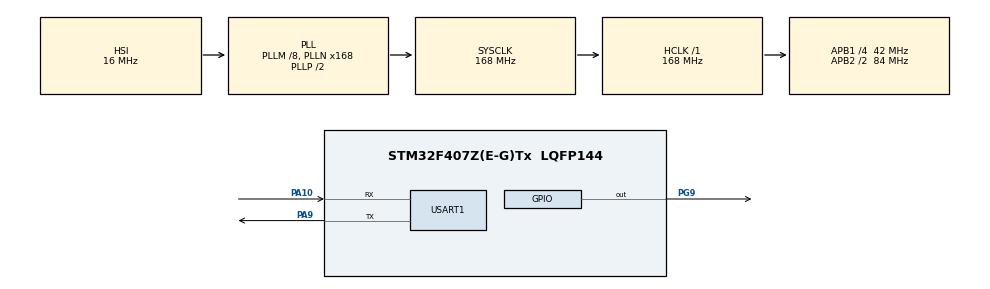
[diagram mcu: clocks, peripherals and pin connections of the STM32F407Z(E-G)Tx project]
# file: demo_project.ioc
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Mcu.Family=STM32F4
Mcu.Name=STM32F407Z(E-G)Tx
Mcu.Package=LQFP144
NVIC.PriorityGroup=NVIC_PRIORITYGROUP_4
NVIC.USART1_IRQn=true\:0\:0\:false\:false\:true\:true\:true
PA10.Mode=Asynchronous
PA10.Signal=USART1_RX
PA9.Mode=Asynchronous
PA9.Signal=USART1_TX
PG9.Signal=GPIO_Output
PH0-OSC_IN.Mode=HSE-External-Oscillator
PH0-OSC_IN.Signal=RCC_OSC_IN
PH1-OSC_OUT.Mode=HSE-External-Oscillator
PH1-OSC_OUT.Signal=RCC_OSC_OUT
ProjectManager.HeapSize=0x2000
ProjectManager.StackSize=0x800
ProjectManager.TargetToolchain=MDK-ARM V5
RCC.48MHZClocksFreq_Value=84000000
RCC.AHBFreq_Value=168000000
RCC.APB1CLKDivider=RCC_HCLK_DIV4
RCC.APB1Freq_Value=42000000
RCC.APB1TimFreq_Value=84000000
RCC.APB2CLKDivider=RCC_HCLK_DIV2
RCC.APB2Freq_Value=84000000
RCC.APB2TimFreq_Value=168000000
RCC.CortexFreq_Value=168000000
RCC.HCLKFreq_Value=168000000
RCC.HSE_VALUE=8000000
RCC.HSI_VALUE=16000000
RCC.LSE_VALUE=32768
RCC.PLLM=8
RCC.PLLN=168
RCC.SYSCLKFreq_VALUE=168000000
RCC.SYSCLKSource=RCC_SYSCLKSOURCE_PLLCLK
RCC.VCOOutputFreq_Value=336000000
STMicroelectronics.X-CUBE-AI.5.0.0.ActivationBufferSizeList=24576
STMicroelectronics.X-CUBE-AI.5.0.0.ApplicationCcArtificialOoIntelligenceJjApplication=Validation
STMicroelectronics.X-CUBE-AI.5.0.0.ArtificialOoIntelligenceJjApplication.cmp_version0=5.0.0
STMicroelectronics.X-CUBE-AI.5.0.0.ArtificialOoIntelligenceJjApplication.component0=Artificial Intelligence
STMicroelectronics.X-CUBE-AI.5.0.0.ArtificialOoIntelligenceJjApplication.description0=AI Application,Validation on Target
STMicroelectronics.X-CUBE-AI.5.0.0.ArtificialOoIntelligenceJjApplication.diagnostic0=This component should operate correctly.
STMicroelectronics.X-CUBE-AI.5.0.0.ArtificialOoIntelligenceJjApplication.documentation0=Documentation/index.html
STMicroelectronics.X-CUBE-AI.5.0.0.ArtificialOoIntelligenceJjApplication.group0=Application
STMicroelectronics.X-CUBE-AI.5.0.0.ArtificialOoIntelligenceJjApplication.paramName0=ApplicationCcArtificialOoIntelligenceJjApplication
STMicroelectronics.X-CUBE-AI.5.0.0.ArtificialOoIntelligenceJjApplication.sevirity0=none
STMicroelectronics.X-CUBE-AI.5.0.0.ArtificialOoIntelligenceJjApplication.variant0=Validation
STMicroelectronics.X-CUBE-AI.5.0.0.ArtificialOoIntelligenceJjApplication_bundle=Application
STMicroelectronics.X-CUBE-AI.5.0.0.ArtificialOoIntelligenceJjApplication_class=ArtificialOoIntelligence
STMicroelectronics.X-CUBE-AI.5.0.0.ArtificialOoIntelligenceJjApplication_name=X-CUBE-AI
STMicroelectronics.X-CUBE-AI.5.0.0.ArtificialOoIntelligenceJjApplication_size=1
STMicroelectronics.X-CUBE-AI.5.0.0.ArtificialOoIntelligenceJjApplication_vendor=STMicroelectronics
STMicroelectronics.X-CUBE-AI.5.0.0.ArtificialOoIntelligenceJjApplication_version=5.0.0
STMicroelectronics.X-CUBE-AI.5.0.0.ArtificialOoIntelligenceJjXAaCUBEAaAI.cmp_version0=5.0.0
STMicroelectronics.X-CUBE-AI.5.0.0.ArtificialOoIntelligenceJjXAaCUBEAaAI.cmp_version1=5.0.0
STMicroelectronics.X-CUBE-AI.5.0.0.ArtificialOoIntelligenceJjXAaCUBEAaAI.component0=Artificial Intelligence
STMicroelectronics.X-CUBE-AI.5.0.0.ArtificialOoIntelligenceJjXAaCUBEAaAI.component1=Artificial Intelligence
STMicroelectronics.X-CUBE-AI.5.0.0.ArtificialOoIntelligenceJjXAaCUBEAaAI.componentDoc0=nofile
STMicroelectronics.X-CUBE-AI.5.0.0.ArtificialOoIntelligenceJjXAaCUBEAaAI.description0=AI Core,Artificial Intelligence for STM32
STMicroelectronics.X-CUBE-AI.5.0.0.ArtificialOoIntelligenceJjXAaCUBEAaAI.description1=AI Application,Validation on Target
STMicroelectronics.X-CUBE-AI.5.0.0.ArtificialOoIntelligenceJjXAaCUBEAaAI.diagnostic0=This component should operate correctly.
STMicroelectronics.X-CUBE-AI.5.0.0.ArtificialOoIntelligenceJjXAaCUBEAaAI.diagnostic1=This component should operate correctly.
STMicroelectronics.X-CUBE-AI.5.0.0.ArtificialOoIntelligenceJjXAaCUBEAaAI.documentation0=Documentation/index.html
STMicroelectronics.X-CUBE-AI.5.0.0.ArtificialOoIntelligenceJjXAaCUBEAaAI.documentation1=Documentation/index.html
STMicroelectronics.X-CUBE-AI.5.0.0.ArtificialOoIntelligenceJjXAaCUBEAaAI.group0=Core
STMicroelectronics.X-CUBE-AI.5.0.0.ArtificialOoIntelligenceJjXAaCUBEAaAI.group1=Application
STMicroelectronics.X-CUBE-AI.5.0.0.ArtificialOoIntelligenceJjXAaCUBEAaAI.paramName0=XAaCUBEAaAICcArtificialOoIntelligenceJjCore
STMicroelectronics.X-CUBE-AI.5.0.0.ArtificialOoIntelligenceJjXAaCUBEAaAI.paramName1=ApplicationCcArtificialOoIntelligenceJjApplication
STMicroelectronics.X-CUBE-AI.5.0.0.ArtificialOoIntelligenceJjXAaCUBEAaAI.sevirity0=none
STMicroelectronics.X-CUBE-AI.5.0.0.ArtificialOoIntelligenceJjXAaCUBEAaAI.sevirity1=none
STMicroelectronics.X-CUBE-AI.5.0.0.ArtificialOoIntelligenceJjXAaCUBEAaAI.variant1=Validation
STMicroelectronics.X-CUBE-AI.5.0.0.ArtificialOoIntelligenceJjXAaCUBEAaAI_bundle=X-CUBE-AI
STMicroelectronics.X-CUBE-AI.5.0.0.ArtificialOoIntelligenceJjXAaCUBEAaAI_class=ArtificialOoIntelligence
STMicroelectronics.X-CUBE-AI.5.0.0.ArtificialOoIntelligenceJjXAaCUBEAaAI_name=X-CUBE-AI
STMicroelectronics.X-CUBE-AI.5.0.0.ArtificialOoIntelligenceJjXAaCUBEAaAI_size=2
STMicroelectronics.X-CUBE-AI.5.0.0.ArtificialOoIntelligenceJjXAaCUBEAaAI_vendor=STMicroelectronics
STMicroelectronics.X-CUBE-AI.5.0.0.ArtificialOoIntelligenceJjXAaCUBEAaAI_version=5.0.0
STMicroelectronics.X-CUBE-AI.5.0.0.BSP.number=1
STMicroelectronics.X-CUBE-AI.5.0.0.HeapSize=0x2000
STMicroelectronics.X-CUBE-AI.5.0.0.InternalRamActivationBufferMaxSize=AI_NETWORK_DATA_ACTIVATIONS_SIZE
STMicroelectronics.X-CUBE-AI.5.0.0.LatestDirectoryUsed-1c7994f23170c33a6f3a2a37c353d476fe9b7e1d63af1343e5945bc54d5a9b8a=C\:\\Users\\40561\\Desktop
STMicroelectronics.X-CUBE-AI.5.0.0.MaximumNumberOfInputLayer=1
STMicroelectronics.X-CUBE-AI.5.0.0.MaximumNumberOfOutputLayer=1
STMicroelectronics.X-CUBE-AI.5.0.0.MaximumSizeOfInputLayer=1080
STMicroelectronics.X-CUBE-AI.5.0.0.MaximumSizeOfOutputLayer=24
STMicroelectronics.X-CUBE-AI.5.0.0.ModelActualCompression-1c7994f23170c33a6f3a2a37c353d476fe9b7e1d63af1343e5945bc54d5a9b8a=0.0
STMicroelectronics.X-CUBE-AI.5.0.0.ModelCompression-1c7994f23170c33a6f3a2a37c353d476fe9b7e1d63af1343e5945bc54d5a9b8a=8
STMicroelectronics.X-CUBE-AI.5.0.0.ModelFlashOccupation-1c7994f23170c33a6f3a2a37c353d476fe9b7e1d63af1343e5945bc54d5a9b8a=375448
STMicroelectronics.X-CUBE-AI.5.0.0.ModelHashList=1c7994f23170c33a6f3a2a37c353d476fe9b7e1d63af1343e5945bc54d5a9b8a
STMicroelectronics.X-CUBE-AI.5.0.0.ModelKind-1c7994f23170c33a6f3a2a37c353d476fe9b7e1d63af1343e5945bc54d5a9b8a=KERAS
STMicroelectronics.X-CUBE-AI.5.0.0.ModelMacc-1c7994f23170c33a6f3a2a37c353d476fe9b7e1d63af1343e5945bc54d5a9b8a=874970
STMicroelectronics.X-CUBE-AI.5.0.0.ModelName-1c7994f23170c33a6f3a2a37c353d476fe9b7e1d63af1343e5945bc54d5a9b8a=network
STMicroelectronics.X-CUBE-AI.5.0.0.ModelNameList=network
STMicroelectronics.X-CUBE-AI.5.0.0.ModelRamOccupation-1c7994f23170c33a6f3a2a37c353d476fe9b7e1d63af1343e5945bc54d5a9b8a=24576
STMicroelectronics.X-CUBE-AI.5.0.0.ModelType-1c7994f23170c33a6f3a2a37c353d476fe9b7e1d63af1343e5945bc54d5a9b8a=Saved model
STMicroelectronics.X-CUBE-AI.5.0.0.NNModelInformation_AchievedCompression-1c7994f23170c33a6f3a2a37c353d476fe9b7e1d63af1343e5945bc54d5a9b8a=0.0
STMicroelectronics.X-CUBE-AI.5.0.0.NNModelInformation_CompressionFactor-1c7994f23170c33a6f3a2a37c353d476fe9b7e1d63af1343e5945bc54d5a9b8a=-0.8729792272819541
STMicroelectronics.X-CUBE-AI.5.0.0.NNModelInformation_EvaluationStatus-1c7994f23170c33a6f3a2a37c353d476fe9b7e1d63af1343e5945bc54d5a9b8a=NOT EVALUATED
STMicroelectronics.X-CUBE-AI.5.0.0.NNModelInformation_HeapSizeNeeded-1c7994f23170c33a6f3a2a37c353d476fe9b7e1d63af1343e5945bc54d5a9b8a=2048
STMicroelectronics.X-CUBE-AI.5.0.0.NNModelInformation_ModelInSizeByName-1c7994f23170c33a6f3a2a37c353d476fe9b7e1d63af1343e5945bc54d5a9b8a={input_0\=1080}
STMicroelectronics.X-CUBE-AI.5.0.0.NNModelInformation_ModelMacc-1c7994f23170c33a6f3a2a37c353d476fe9b7e1d63af1343e5945bc54d5a9b8a=874970
STMicroelectronics.X-CUBE-AI.5.0.0.NNModelInformation_ModelName-1c7994f23170c33a6f3a2a37c353d476fe9b7e1d63af1343e5945bc54d5a9b8a=network
STMicroelectronics.X-CUBE-AI.5.0.0.NNModelInformation_ModelOutSizeByName-1c7994f23170c33a6f3a2a37c353d476fe9b7e1d63af1343e5945bc54d5a9b8a={dense_3_nl\=24}
STMicroelectronics.X-CUBE-AI.5.0.0.NNModelInformation_ModelRam-1c7994f23170c33a6f3a2a37c353d476fe9b7e1d63af1343e5945bc54d5a9b8a=24576
STMicroelectronics.X-CUBE-AI.5.0.0.NNModelInformation_ModelRom-1c7994f23170c33a6f3a2a37c353d476fe9b7e1d63af1343e5945bc54d5a9b8a=375448
STMicroelectronics.X-CUBE-AI.5.0.0.NNModelInformation_ModelSize-1c7994f23170c33a6f3a2a37c353d476fe9b7e1d63af1343e5945bc54d5a9b8a=2955800
STMicroelectronics.X-CUBE-AI.5.0.0.NNModelInformation_NbOfParameters-1c7994f23170c33a6f3a2a37c353d476fe9b7e1d63af1343e5945bc54d5a9b8a=738950
STMicroelectronics.X-CUBE-AI.5.0.0.StackSize=0x800
STMicroelectronics.X-CUBE-AI.5.0.0.WorkingBufferStartAddrList=0xFFFFFFFF
STMicroelectronics.X-CUBE-AI.5.0.0.XAaCUBEAaAICcArtificialOoIntelligenceJjCore=true
STMicroelectronics.X-CUBE-AI.5.0.0.copyWeightToRam-1c7994f23170c33a6f3a2a37c353d476fe9b7e1d63af1343e5945bc54d5a9b8a=false
STMicroelectronics.X-CUBE-AI.5.0.0.useInputAllocation-1c7994f23170c33a6f3a2a37c353d476fe9b7e1d63af1343e5945bc54d5a9b8a=false
STMicroelectronics.X-CUBE-AI.5.0.00.BSP.STBoard=false
STMicroelectronics.X-CUBE-AI.5.0.00.BSP.api=Unknown
STMicroelectronics.X-CUBE-AI.5.0.00.BSP.condition=\!SEMArtificialOoIntelligenceJjApplicationJjApplicationTemplate
STMicroelectronics.X-CUBE-AI.5.0.00.BSP.i2caddr=0
STMicroelectronics.X-CUBE-AI.5.0.00.BSP.instance=USART1
STMicroelectronics.X-CUBE-AI.5.0.00.BSP.ip=USART
STMicroelectronics.X-CUBE-AI.5.0.00.BSP.mode=Asynchronous
STMicroelectronics.X-CUBE-AI.5.0.00.BSP.name=COM Port
STMicroelectronics.X-CUBE-AI.5.0.00.BSP.solution=USART1
STMicroelectronics.X-CUBE-AI.5.0.0_ArtificialOoIntelligenceJjApplication_RteComponent0=\#define AI_VALIDATION
STMicroelectronics.X-CUBE-AI.5.0.0_ArtificialOoIntelligenceJjApplication_RteComponentsize=1
STMicroelectronics.X-CUBE-AI.5.0.0_ArtificialOoIntelligenceJjXAaCUBEAaAI_RteComponentsize=0
STMicroelectronics.X-CUBE-AI.5.0.0_MwName0=X-CUBE-AI
STMicroelectronics.X-CUBE-AI.5.0.0_MwName1=Application
STMicroelectronics.X-CUBE-AI.5.0.0_NumberOfMw=2
STMicroelectronics.X-CUBE-AI.5.0.0_description=Artificial Intelligence
STMicroelectronics.X-CUBE-AI.5.0.0_license=SLA0048.txt
USART1.VirtualMode=VM_ASYNC
VP_CRC_VS_CRC.Mode=CRC_Activate
VP_STMicroelectronics.X-CUBE-AI_VS_ArtificialOoIntelligenceJjApplication_5.0.0.Mode=ArtificialOoIntelligenceJjApplication
VP_STMicroelectronics.X-CUBE-AI_VS_ArtificialOoIntelligenceJjXAaCUBEAaAI_5.0.0.Mode=ArtificialOoIntelligenceJjXAaCUBEAaAI
board=custom

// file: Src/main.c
/* USER CODE BEGIN Header */
/**
  ******************************************************************************
  * @file           : main.c
  * @brief          : Main program body
  ******************************************************************************
  * @attention
  *
  * <h2><center>&copy; Copyright (c) 2019 STMicroelectronics.
  * All rights reserved.</center></h2>
  *
  * This software component is licensed by ST under BSD 3-Clause license,
  * the "License"; You may not use this file except in compliance with the
  * License. You may obtain a copy of the License at:
  *                        opensource.org/licenses/BSD-3-Clause
  *
  ******************************************************************************
  */
/* USER CODE END Header */

#include "main.h"
#include "crc.h"
#include "usart.h"
#include "gpio.h"
#include "app_x-cube-ai.h"
#include <stdio.h>

/* USER CODE BEGIN PV */
static uint8_t fac_us = 0;  //us延时倍乘数
/* USER CODE END PV */

void SystemClock_Config(void);

/* USER CODE BEGIN 0 */
void delay_us(uint32_t nus)
{
	uint32_t temp;
	SysTick->LOAD = nus * fac_us;			   //时间加载
	SysTick->VAL  = 0x00;					   //清空计数器
	SysTick->CTRL |= SysTick_CTRL_ENABLE_Msk;  //开始倒数
	do
	{
		temp = SysTick->CTRL;
	} while ((temp & 0x01) && !(temp & (1 << 16)));  //等待时间到达
	SysTick->CTRL &= ~SysTick_CTRL_ENABLE_Msk;		 //关闭计数器
	SysTick->VAL = 0X00;							 //清空计数器
}
void delay_ms(uint16_t nms)
{
	delay_us((uint32_t)(nms * 1000));  //普通方式延时
}
/* USER CODE END 0 */

int main(void)
{
  /* USER CODE BEGIN 1 */
	uint32_t count = 0;
  /* USER CODE END 1 */

  /* MCU Configuration--------------------------------------------------------*/

  /* Reset of all peripherals, Initializes the Flash interface and the Systick. */
  HAL_Init();

  /* Configure the system clock */
  SystemClock_Config();

  /* Initialize all configured peripherals */
  MX_GPIO_Init();
  MX_CRC_Init();
  MX_USART1_UART_Init();
	printf("test start\r\n");
  printf("test start\r\n");
  MX_X_CUBE_AI_Init();

  /* Infinite loop */
	while (1)
	{

  MX_X_CUBE_AI_Process();
    /* USER CODE BEGIN 3 */
		for (count = 0; count < 1000000; count++)
		{
			;
		}
		HAL_GPIO_WritePin(GPIOG, GPIO_PIN_9, GPIO_PIN_RESET);
		for (count = 0; count < 1000000; count++)
		{
			;
		}
		HAL_GPIO_WritePin(GPIOG, GPIO_PIN_9, GPIO_PIN_SET);
	}
  /* USER CODE END 3 */
}

void SystemClock_Config(void)
{
  RCC_OscInitTypeDef RCC_OscInitStruct = {0};
  RCC_ClkInitTypeDef RCC_ClkInitStruct = {0};

  /** Configure the main internal regulator output voltage
  */
  __HAL_RCC_PWR_CLK_ENABLE();
  __HAL_PWR_VOLTAGESCALING_CONFIG(PWR_REGULATOR_VOLTAGE_SCALE1);
  /** Initializes the CPU, AHB and APB busses clocks
  */
  RCC_OscInitStruct.OscillatorType = RCC_OSCILLATORTYPE_HSI;
  RCC_OscInitStruct.HSIState = RCC_HSI_ON;
  RCC_OscInitStruct.HSICalibrationValue = RCC_HSICALIBRATION_DEFAULT;
  RCC_OscInitStruct.PLL.PLLState = RCC_PLL_ON;
  RCC_OscInitStruct.PLL.PLLSource = RCC_PLLSOURCE_HSI;
  RCC_OscInitStruct.PLL.PLLM = 8;
  RCC_OscInitStruct.PLL.PLLN = 168;
  RCC_OscInitStruct.PLL.PLLP = RCC_PLLP_DIV2;
  RCC_OscInitStruct.PLL.PLLQ = 4;
  if (HAL_RCC_OscConfig(&RCC_OscInitStruct) != HAL_OK)
  {
    Error_Handler();
  }
  /** Initializes the CPU, AHB and APB busses clocks
  */
  RCC_ClkInitStruct.ClockType = RCC_CLOCKTYPE_HCLK|RCC_CLOCKTYPE_SYSCLK
                              |RCC_CLOCKTYPE_PCLK1|RCC_CLOCKTYPE_PCLK2;
  RCC_ClkInitStruct.SYSCLKSource = RCC_SYSCLKSOURCE_PLLCLK;
  RCC_ClkInitStruct.AHBCLKDivider = RCC_SYSCLK_DIV1;
  RCC_ClkInitStruct.APB1CLKDivider = RCC_HCLK_DIV4;
  RCC_ClkInitStruct.APB2CLKDivider = RCC_HCLK_DIV2;

  if (HAL_RCC_ClockConfig(&RCC_ClkInitStruct, FLASH_LATENCY_5) != HAL_OK)
  {
    Error_Handler();
  }
}

void Error_Handler(void)
{
}

/************************ (C) COPYRIGHT STMicroelectronics *****END OF FILE****/
